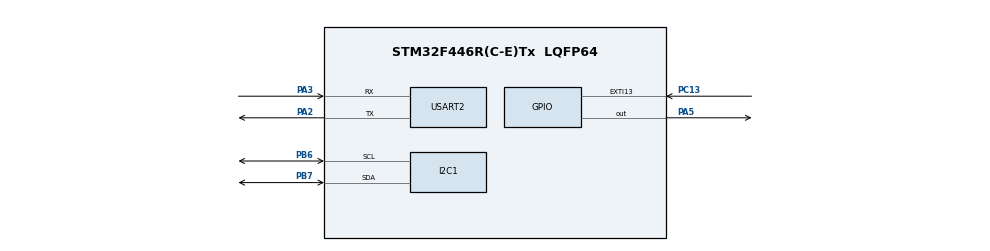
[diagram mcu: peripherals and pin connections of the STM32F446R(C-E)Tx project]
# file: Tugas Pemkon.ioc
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Mcu.Family=STM32F4
Mcu.Name=STM32F446R(C-E)Tx
Mcu.Package=LQFP64
NVIC.PriorityGroup=NVIC_PRIORITYGROUP_4
PA13.Mode=Serial_Wire
PA13.Signal=SYS_JTMS-SWDIO
PA14.Mode=Serial_Wire
PA14.Signal=SYS_JTCK-SWCLK
PA2.Mode=Asynchronous
PA2.Signal=USART2_TX
PA3.Mode=Asynchronous
PA3.Signal=USART2_RX
PA5.Signal=GPIO_Output
PB6.Mode=I2C
PB6.Signal=I2C1_SCL
PB7.Mode=I2C
PB7.Signal=I2C1_SDA
PC13.Signal=GPXTI13
PC14-OSC32_IN.Signal=RCC_OSC32_IN
PC15-OSC32_OUT.Signal=RCC_OSC32_OUT
PH0-OSC_IN.Signal=RCC_OSC_IN
PH1-OSC_OUT.Signal=RCC_OSC_OUT
ProjectManager.HeapSize=0x200
ProjectManager.StackSize=0x400
ProjectManager.TargetToolchain=STM32CubeIDE
RCC.CortexFreq_Value=16000000
RCC.USBFreq_Value=96000000
RCC.VCOOutputFreq_Value=192000000
USART2.VirtualMode=VM_ASYNC
board=custom

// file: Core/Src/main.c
#include "main.h"
#include "i2c.h"
#include "usart.h"
#include "gpio.h"
#include "stdio.h"
#include "string.h"
#include "MAX30102/MAX30102.h"

#define UART_BUFFER_SIZE  (32U)

static char UartBuffer[UART_BUFFER_SIZE];

static void SystemClock_Config(void);
static void MX_NVIC_Init(void);
static void UART2_SendString(const char *s);

/* USER CODE BEGIN 0 */
static void UART2_SendString(const char *s)
{
  if (s != NULL)
  {
    (void)HAL_UART_Transmit(&huart2, (uint8_t *)s, (uint16_t)strlen(s), 1000U);
  }
}
/* USER CODE END 0 */

int main(void)
{
  /* MCU Configuration--------------------------------------------------------*/
  HAL_Init();
  SystemClock_Config();
  MX_GPIO_Init();
  MX_I2C1_Init();
  MX_USART2_UART_Init();
  MX_NVIC_Init();

  UART2_SendString("START\n\r");
  Max30102_Init(&hi2c1);

  for (;;)
  {
    Max30102_Task();

    (void)sprintf(UartBuffer, "%c[2J%c[H", 27, 27);
    UART2_SendString(UartBuffer);

    (void)sprintf(UartBuffer, "HR: %d\n\rSpO2: %d\n\r", Max30102_GetHeartRate(), Max30102_GetSpO2Value());
    UART2_SendString(UartBuffer);
  }
}

static void SystemClock_Config(void)
{
  RCC_OscInitTypeDef RCC_OscInitStruct = {0};
  RCC_ClkInitTypeDef RCC_ClkInitStruct = {0};

  __HAL_RCC_PWR_CLK_ENABLE();
  __HAL_PWR_VOLTAGESCALING_CONFIG(PWR_REGULATOR_VOLTAGE_SCALE2);

  RCC_OscInitStruct.OscillatorType = RCC_OSCILLATORTYPE_HSI;
  RCC_OscInitStruct.HSIState = RCC_HSI_ON;
  RCC_OscInitStruct.HSICalibrationValue = RCC_HSICALIBRATION_DEFAULT;
  RCC_OscInitStruct.PLL.PLLState = RCC_PLL_ON;
  RCC_OscInitStruct.PLL.PLLSource = RCC_PLLSOURCE_HSI;
  RCC_OscInitStruct.PLL.PLLM = 8U;
  RCC_OscInitStruct.PLL.PLLN = 84U;
  RCC_OscInitStruct.PLL.PLLP = RCC_PLLP_DIV2;
  RCC_OscInitStruct.PLL.PLLQ = 4U;

  if (HAL_RCC_OscConfig(&RCC_OscInitStruct) != HAL_OK)
  {
    Error_Handler();
  }

  RCC_ClkInitStruct.ClockType = RCC_CLOCKTYPE_HCLK | RCC_CLOCKTYPE_SYSCLK |
                                RCC_CLOCKTYPE_PCLK1 | RCC_CLOCKTYPE_PCLK2;
  RCC_ClkInitStruct.SYSCLKSource = RCC_SYSCLKSOURCE_PLLCLK;
  RCC_ClkInitStruct.AHBCLKDivider = RCC_SYSCLK_DIV1;
  RCC_ClkInitStruct.APB1CLKDivider = RCC_HCLK_DIV2;
  RCC_ClkInitStruct.APB2CLKDivider = RCC_HCLK_DIV1;

  if (HAL_RCC_ClockConfig(&RCC_ClkInitStruct, FLASH_LATENCY_2) != HAL_OK)
  {
    Error_Handler();
  }
}

static void MX_NVIC_Init(void)
{
  HAL_NVIC_SetPriority(EXTI9_5_IRQn, 1U, 0U);
  HAL_NVIC_EnableIRQ(EXTI9_5_IRQn);
}

void HAL_GPIO_EXTI_Callback(uint16_t GPIO_Pin)
{
  if (GPIO_Pin == INT_Pin)
  {
    Max30102_InterruptCallback();
  }
}

void Error_Handler(void)
{
  for (;;) {} /* Stay in loop if error occurs */
}
